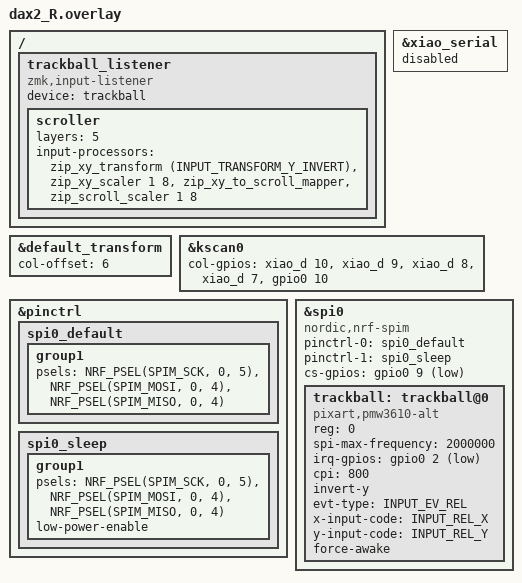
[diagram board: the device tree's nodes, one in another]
#include "dax2.dtsi"
#include <input/processors.dtsi>
#include <dt-bindings/zmk/input_transform.h>
#include <zephyr/dt-bindings/input/input-event-codes.h>

&xiao_serial {
  status = "disabled";
};

&default_transform {
  col-offset = <6>;
};

&kscan0 {
  col-gpios
    = <&xiao_d 10 GPIO_ACTIVE_HIGH>
    , <&xiao_d 9 GPIO_ACTIVE_HIGH>
    , <&xiao_d 8 GPIO_ACTIVE_HIGH>
    , <&xiao_d 7 GPIO_ACTIVE_HIGH>
    , <&gpio0 10 GPIO_ACTIVE_HIGH>
    ;
};

/ {
  trackball_listener {
    compatible = "zmk,input-listener";
    device = <&trackball>;

    // レイヤー5でスクロールモード
    scroller {
      layers = <5>;
      input-processors = <
        &zip_xy_transform (INPUT_TRANSFORM_Y_INVERT)  // スクロール時Y軸反転（デバイスの反転を打ち消す）
        &zip_xy_scaler 1 8                             // XYを1/8に減速
        &zip_xy_to_scroll_mapper                       // XY→スクロール変換
        &zip_scroll_scaler 1 8                         // スクロールを1/8に減速（合計1/64）
      >;
    };
  };
};

&pinctrl {
  spi0_default: spi0_default {
    group1 {
      psels = <NRF_PSEL(SPIM_SCK, 0, 5)>, // SCLK
        <NRF_PSEL(SPIM_MOSI, 0, 4)>,      // SDIO
        <NRF_PSEL(SPIM_MISO, 0, 4)>;      // SDIO
    };
  };

  spi0_sleep: spi0_sleep {
    group1 {
      psels = <NRF_PSEL(SPIM_SCK, 0, 5)>, // SCLK
        <NRF_PSEL(SPIM_MOSI, 0, 4)>,      // SDIO
        <NRF_PSEL(SPIM_MISO, 0, 4)>;      // SDIO
      low-power-enable;
    };
  };
};

&spi0 {
  status = "okay";
  compatible = "nordic,nrf-spim";
  pinctrl-0 = <&spi0_default>;
  pinctrl-1 = <&spi0_sleep>;
  pinctrl-names = "default", "sleep";
  cs-gpios = <&gpio0 9 GPIO_ACTIVE_LOW>; // CS

  trackball: trackball@0 {
    status = "okay";
    compatible = "pixart,pmw3610-alt";  // badjeff版のcompatible
    reg = <0>;
    spi-max-frequency = <2000000>;
    irq-gpios = <&gpio0 2 (GPIO_ACTIVE_LOW | GPIO_PULL_UP)>; // Motion

    // badjeff版の設定
    cpi = <800>;           // CPI設定（デバイスツリーへ移行）
    invert-y;              // Y軸反転（180度回転）

    // 必須プロパティ
    evt-type = <INPUT_EV_REL>;
    x-input-code = <INPUT_REL_X>;
    y-input-code = <INPUT_REL_Y>;

    // 常時125Hz動作（旧ドライバと同等）
    force-awake;
  };
};
